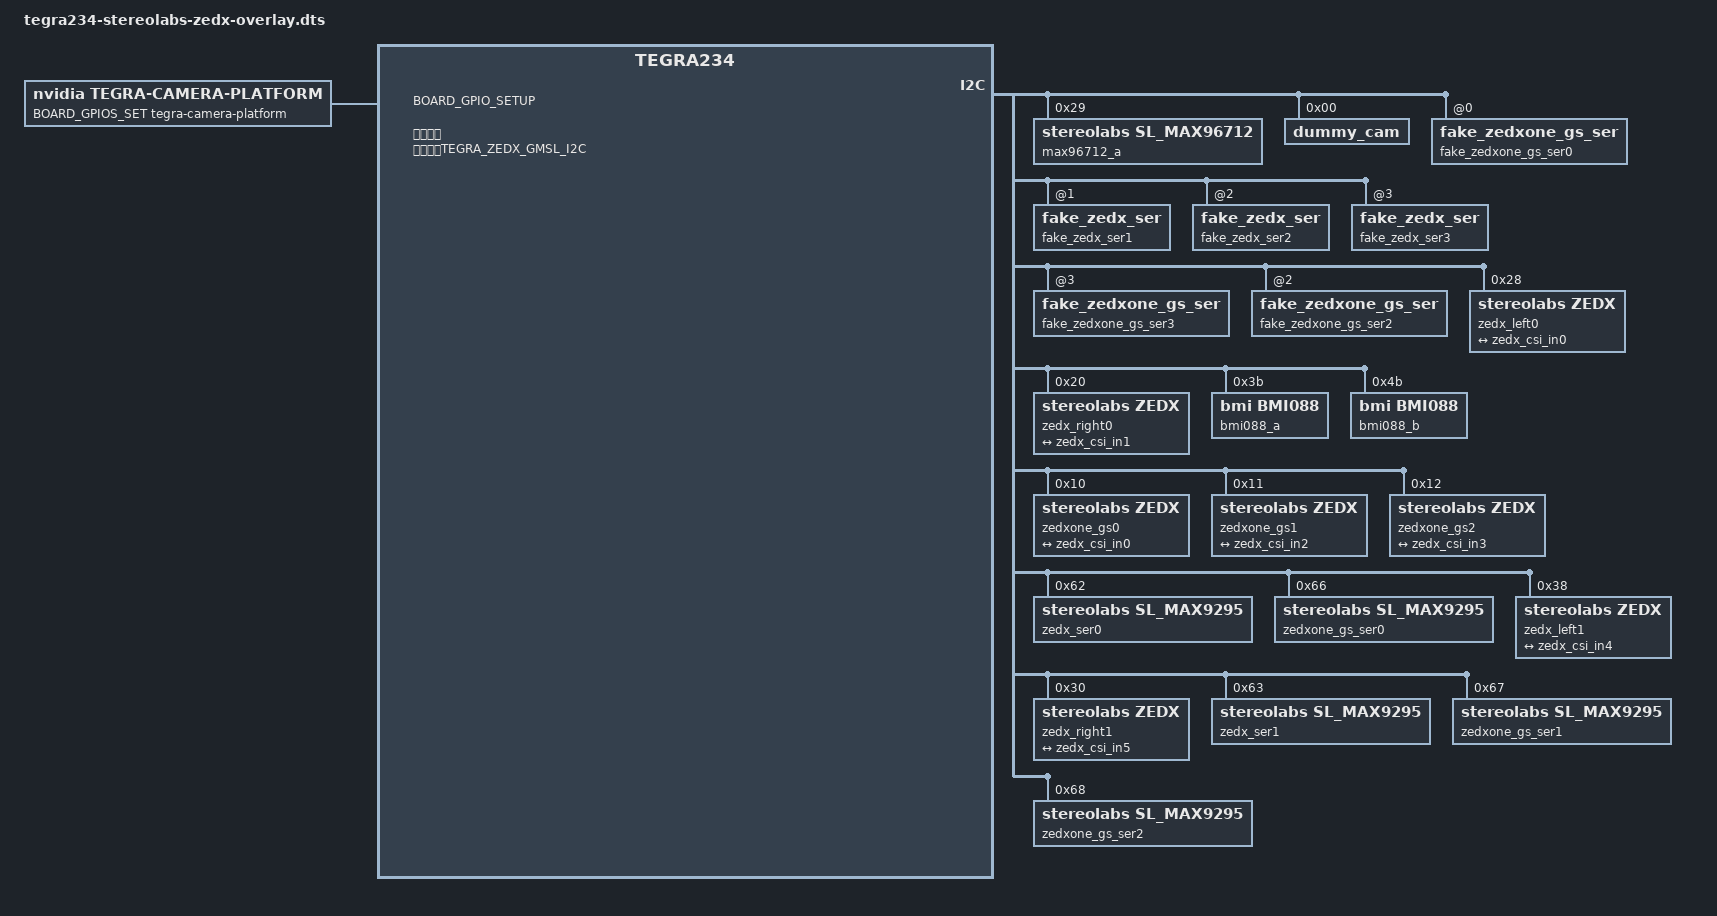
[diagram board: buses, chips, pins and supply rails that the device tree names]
// SPDX-License-Identifier: GPL-2.0-only
// Stereolabs ZED X / ZED X One GS GMSL overlay.

/dts-v1/;
/plugin/;

#include <dt-bindings/gpio/tegra234-gpio.h>
#include <dt-bindings/clock/tegra234-clock.h>
#include <dt-bindings/tegra234-p3737-0000+p3701-0000.h>
/* BOARD_CONFIG_MARKER - Do not modify, auto-generated by Makefile */
#include "tegra234-stereolabs-zedx-config.dtsi"

#define NUM_LANES	2

#define STR(x) #x
#define XSTR(x) STR(x)

#define ZED_ORIN_CLKS \
	clocks = <&bpmp TEGRA234_CLK_EXTPERIPH1>, \
		<&bpmp TEGRA234_CLK_EXTPERIPH1>; \
	clock-names = "extperiph1", "pllp_grtba"; \
	mclk = "extperiph1";

#define AR0234_MODES(VC_ID, OPT_CSI_SERIAL, LANE_POLARITY) \
	physical_w = "15.0"; \
	physical_h = "12.5"; \
	post_crop_frame_drop = "0"; \
	use_sensor_mode_id = "true"; \
	mode0 { \
		mclk_khz = "24000"; \
		num_lanes = XSTR(NUM_LANES); \
		tegra_sinterface = OPT_CSI_SERIAL; \
		lane_polarity = LANE_POLARITY; \
		vc_id = VC_ID; \
		discontinuous_clk = "no"; \
		dpcm_enable = "false"; \
		cil_settletime = "0"; \
		dynamic_pixel_bit_depth = "10"; \
		csi_pixel_bit_depth = "10"; \
		mode_type = "bayer"; \
		pixel_phase = "grbg"; \
		active_w = "1920"; \
		active_h = "1200"; \
		readout_orientation = "0"; \
		line_length = "12496"; \
		inherent_gain = "1"; \
		mclk_multiplier = "3.01"; \
		pix_clk_hz = "229500000"; \
		serdes_pix_clk_hz = "299000000"; \
		gain_factor = "100"; \
		min_gain_val = "100"; \
		max_gain_val = "1600"; \
		step_gain_val = "1"; \
		default_gain = "100"; \
		min_hdr_ratio = "1"; \
		max_hdr_ratio = "1"; \
		framerate_factor = "1000000"; \
		min_framerate = "15000000"; \
		max_framerate = "60000000"; \
		step_framerate = "15000000"; \
		default_framerate = "30000000"; \
		exposure_factor = "1000000"; \
		min_exp_time = "28"; \
		max_exp_time = "66000"; \
		step_exp_time = "1"; \
		default_exp_time = "13000"; \
		embedded_metadata_height = "0"; \
	}; \
	mode1 { \
		mclk_khz = "24000"; \
		num_lanes = XSTR(NUM_LANES); \
		tegra_sinterface = OPT_CSI_SERIAL; \
		lane_polarity = LANE_POLARITY; \
		vc_id = VC_ID; \
		discontinuous_clk = "no"; \
		dpcm_enable = "false"; \
		cil_settletime = "0"; \
		dynamic_pixel_bit_depth = "10"; \
		csi_pixel_bit_depth = "10"; \
		mode_type = "bayer"; \
		pixel_phase = "grbg"; \
		active_w = "960"; \
		active_h = "600"; \
		readout_orientation = "0"; \
		line_length = "6248"; \
		inherent_gain = "1"; \
		mclk_multiplier = "3.01"; \
		pix_clk_hz = "229500000"; \
		serdes_pix_clk_hz = "299000000"; \
		gain_factor = "100"; \
		min_gain_val = "100"; \
		max_gain_val = "1600"; \
		step_gain_val = "1"; \
		default_gain = "100"; \
		min_hdr_ratio = "1"; \
		max_hdr_ratio = "1"; \
		framerate_factor = "1000000"; \
		min_framerate = "15000000"; \
		max_framerate = "120000000"; \
		step_framerate = "15000000"; \
		default_framerate = "120000000"; \
		exposure_factor = "1000000"; \
		min_exp_time = "28"; \
		max_exp_time = "66000"; \
		step_exp_time = "1"; \
		default_exp_time = "8000"; \
		embedded_metadata_height = "0"; \
	}; \
	mode2 { \
		mclk_khz = "24000"; \
		num_lanes = XSTR(NUM_LANES); \
		tegra_sinterface = OPT_CSI_SERIAL; \
		lane_polarity = LANE_POLARITY; \
		vc_id = VC_ID; \
		discontinuous_clk = "no"; \
		dpcm_enable = "false"; \
		cil_settletime = "0"; \
		dynamic_pixel_bit_depth = "10"; \
		csi_pixel_bit_depth = "10"; \
		mode_type = "bayer"; \
		pixel_phase = "grbg"; \
		active_w = "1920"; \
		active_h = "1080"; \
		readout_orientation = "0"; \
		line_length = "12496"; \
		inherent_gain = "1"; \
		mclk_multiplier = "3.01"; \
		pix_clk_hz = "229500000"; \
		serdes_pix_clk_hz = "299000000"; \
		gain_factor = "100"; \
		min_gain_val = "100"; \
		max_gain_val = "1600"; \
		step_gain_val = "1"; \
		default_gain = "100"; \
		min_hdr_ratio = "1"; \
		max_hdr_ratio = "1"; \
		framerate_factor = "1000000"; \
		min_framerate = "15000000"; \
		max_framerate = "60000000"; \
		step_framerate = "15000000"; \
		default_framerate = "30000000"; \
		exposure_factor = "1000000"; \
		min_exp_time = "28"; \
		max_exp_time = "66000"; \
		step_exp_time = "1"; \
		default_exp_time = "13000"; \
		embedded_metadata_height = "0"; \
	};

/ {
	overlay-name = ZEDX_OVERLAY_NAME;
	jetson-header-name = "Jetson AGX CSI Connector";
	compatible = JETSON_COMPATIBLE;

	fragment@0 {
		target-path = "/";
		__overlay__ {
			tegra-capture-vi {
				num-channels = <6>;
				ports {
					#address-cells = <1>;
					#size-cells = <0>;

					port@0 {
						reg = <0>;
						zedx_vi_in0: endpoint {
							vc-id = <0>;
							port-index = <0>;
							bus-width = <NUM_LANES>;
							remote-endpoint = <&zedx_csi_out0>;
						};
					};

					port@1 {
						reg = <1>;
						zedx_vi_in1: endpoint {
							vc-id = <1>;
							port-index = <0>;
							bus-width = <NUM_LANES>;
							remote-endpoint = <&zedx_csi_out1>;
						};
					};

					port@2 {
						reg = <2>;
						zedx_vi_in2: endpoint {
							vc-id = <0>;
							port-index = <1>;
							bus-width = <NUM_LANES>;
							remote-endpoint = <&zedx_csi_out2>;
						};
					};

					port@3 {
						reg = <3>;
						zedx_vi_in3: endpoint {
							vc-id = <0>;
							port-index = <2>;
							bus-width = <NUM_LANES>;
							remote-endpoint = <&zedx_csi_out3>;
						};
					};

					port@4 {
						reg = <4>;
						zedx_vi_in4: endpoint {
							vc-id = <0>;
							port-index = <3>;
							bus-width = <NUM_LANES>;
							remote-endpoint = <&zedx_csi_out4>;
						};
					};

					port@5 {
						reg = <5>;
						zedx_vi_in5: endpoint {
							vc-id = <1>;
							port-index = <3>;
							bus-width = <NUM_LANES>;
							remote-endpoint = <&zedx_csi_out5>;
						};
					};
				};
			};

			BOARD_GPIOS_SET

			tegra-camera-platform {
				compatible = "nvidia, tegra-camera-platform";
				num_csi_lanes = <4>;
				max_lane_speed = <2000000>;
				min_bits_per_pixel = <10>;
				vi_peak_byte_per_pixel = <2>;
				vi_bw_margin_pct = <25>;
				isp_peak_byte_per_pixel = <5>;
				isp_bw_margin_pct = <25>;

				modules {
					module0 {
						badge = "zedx_left_ar0234";
						position = "frontleft";
						orientation = "1";
						drivernode0 {
							pcl_id = "v4l2_sensor";
							devname = ZEDX_DEVNAME_LEFT0;
							proc-device-tree = ZEDX_PROC_LEFT0;
						};
					};

					module1 {
						badge = "zedx_right_ar0234";
						position = "frontright";
						orientation = "1";
						drivernode0 {
							pcl_id = "v4l2_sensor";
							devname = ZEDX_DEVNAME_RIGHT0;
							proc-device-tree = ZEDX_PROC_RIGHT0;
						};
					};

					module2 {
						badge = "zedxone_gs1_ar0234";
						position = "front";
						orientation = "1";
						drivernode0 {
							pcl_id = "v4l2_sensor";
							devname = ZEDX_DEVNAME_ONE_GS1;
							proc-device-tree = ZEDX_PROC_ONE_GS1;
						};
					};

					module3 {
						badge = "zedxone_gs2_ar0234";
						position = "rear";
						orientation = "1";
						drivernode0 {
							pcl_id = "v4l2_sensor";
							devname = ZEDX_DEVNAME_ONE_GS2;
							proc-device-tree = ZEDX_PROC_ONE_GS2;
						};
					};

					module4 {
						badge = "zedx_left1_ar0234";
						position = "rearleft";
						orientation = "1";
						drivernode0 {
							pcl_id = "v4l2_sensor";
							devname = ZEDX_DEVNAME_LEFT1;
							proc-device-tree = ZEDX_PROC_LEFT1;
						};
					};

					module5 {
						badge = "zedx_right1_ar0234";
						position = "rearright";
						orientation = "1";
						drivernode0 {
							pcl_id = "v4l2_sensor";
							devname = ZEDX_DEVNAME_RIGHT1;
							proc-device-tree = ZEDX_PROC_RIGHT1;
						};
					};
				};
			};

			bus@0 {
				BOARD_GPIO_SETUP

				/* I2C bus 3 - MAX96712 DesA directly, no PCA9546 mux. */
				TEGRA_ZEDX_GMSL_I2C {
					#address-cells = <1>;
					#size-cells = <0>;

					max96712_a@29 {
						compatible = "stereolabs,sl_max96712";
						reg = <0x29>;
						channel = "a";
						pwr-gpio = ZEDX_DSER_PWR_GPIO;
						status = "okay";

						camera-serializers = <
							/* GMSL 0: ZED X */
							&zedx_ser0
							&fake_zedxone_gs_ser0
							/* GMSL 1: ZED X One GS */
							&fake_zedx_ser1
							&zedxone_gs_ser1
							/* GMSL 2: ZED X One GS */
							&fake_zedx_ser2
							&zedxone_gs_ser2
							/* GMSL 3: ZED X */
							&zedx_ser1
							&fake_zedxone_gs_ser3
						>;
					};

					dummy_cam: dummy_cam@0 {
						reg = <0>;
					};

					fake_zedxone_gs_ser0: fake_zedxone_gs_ser@0 {
						camera_model = "zedonegs";
						zedx-id = "-1";
						camera-sensors = <&dummy_cam>;
					};

					fake_zedx_ser1: fake_zedx_ser@1 {
						camera_model = "zedx";
						zedx-id = "-1";
						camera-sensors = <&dummy_cam &dummy_cam>;
					};

					fake_zedx_ser2: fake_zedx_ser@2 {
						camera_model = "zedx";
						zedx-id = "-1";
						camera-sensors = <&dummy_cam &dummy_cam>;
					};

					fake_zedx_ser3: fake_zedx_ser@3 {
						camera_model = "zedx";
						zedx-id = "-1";
						camera-sensors = <&dummy_cam &dummy_cam>;
					};

					fake_zedxone_gs_ser3: fake_zedxone_gs_ser@3 {
						camera_model = "zedonegs";
						zedx-id = "-1";
						camera-sensors = <&dummy_cam>;
					};

					/*
					 * Keep unused placeholders in the source so other physical
					 * plug orders can be tested by reordering camera-serializers.
					 */
					fake_zedxone_gs_ser2: fake_zedxone_gs_ser@2 {
						camera_model = "zedonegs";
						zedx-id = "-1";
						camera-sensors = <&dummy_cam>;
					};

					zedx_left0: zedx_left_0@28 {
						compatible = "stereolabs,zedx";
						reg = <0x28>;

						ZED_ORIN_CLKS

						devnode = "video0";
						sync_sensor = "ZED_CAM0";
						sync_sensor_index = <1>;

						zedx-id = "0";
						channel = "a";

						has-eeprom;
						eeprom-addr = <0x54>;

						AR0234_MODES("0", "serial_a", "0")

						ports {
							#address-cells = <1>;
							#size-cells = <0>;
							port@0 {
								reg = <0>;
								zedx_ar0234_out0: endpoint {
									vc-id = <0>;
									port-index = <0>;
									opt-csi-port = "e";
									bus-width = <NUM_LANES>;
									i2c-cc = <0>;
									remote-endpoint = <&zedx_csi_in0>;
								};
							};
						};
					};

					zedx_right0: zedx_right_0@20 {
						compatible = "stereolabs,zedx";
						reg = <0x20>;

						ZED_ORIN_CLKS

						devnode = "video1";
						sync_sensor = "ZED_CAM0";
						sync_sensor_index = <2>;

						zedx-id = "0";
						channel = "a";

						has-eeprom;
						eeprom-addr = <0x54>;

						AR0234_MODES("1", "serial_a", "0")

						ports {
							#address-cells = <1>;
							#size-cells = <0>;
							port@0 {
								reg = <0>;
								zedx_ar0234_out1: endpoint {
									vc-id = <1>;
									port-index = <0>;
									opt-csi-port = "e";
									bus-width = <NUM_LANES>;
									i2c-cc = <0>;
									remote-endpoint = <&zedx_csi_in1>;
								};
							};
						};
					};

					bmi088_a: bmi088_a@3b {
						compatible = "bmi,bmi088";
						reg = <0x3b>;
						accel_i2c_addr = <0x3c>;
						accel_matrix = [01 00 00 00 01 00 00 00 01];
						gyro_matrix = [01 00 00 00 01 00 00 00 01];
					};

					bmi088_b: bmi088_b@4b {
						compatible = "bmi,bmi088";
						reg = <0x4b>;
						accel_i2c_addr = <0x4c>;
						accel_matrix = [01 00 00 00 01 00 00 00 01];
						gyro_matrix = [01 00 00 00 01 00 00 00 01];
					};

					zedxone_gs0: zedxone_gs_0@10 {
						compatible = "stereolabs,zedx";
						reg = <0x10>;

						ZED_ORIN_CLKS

						devnode = "video0";
						sync_sensor = "ZEDXONE_CAM0";
						sync_sensor_index = <1>;

						zedx-id = "4";
						channel = "a";

						has-eeprom;
						eeprom-addr = <0x56>;

						AR0234_MODES("0", "serial_a", "0")

						ports {
							#address-cells = <1>;
							#size-cells = <0>;
							port@0 {
								reg = <0>;
								zedxone_gs_out0: endpoint {
									vc-id = <0>;
									port-index = <0>;
									opt-csi-port = "e";
									bus-width = <NUM_LANES>;
									i2c-cc = <0>;
									remote-endpoint = <&zedx_csi_in0>;
								};
							};
						};
					};

					zedxone_gs1: zedxone_gs_1@11 {
						compatible = "stereolabs,zedx";
						reg = <0x11>;

						ZED_ORIN_CLKS

						devnode = "video2";
						sync_sensor = "ZEDXONE_CAM1";
						sync_sensor_index = <1>;

						zedx-id = "5";
						channel = "a";

						has-eeprom;
						eeprom-addr = <0x56>;

						AR0234_MODES("0", "serial_b", "0")

						ports {
							#address-cells = <1>;
							#size-cells = <0>;
							port@0 {
								reg = <0>;
								zedxone_gs_out1: endpoint {
									vc-id = <0>;
									port-index = <1>;
									opt-csi-port = "f";
									bus-width = <NUM_LANES>;
									i2c-cc = <0>;
									remote-endpoint = <&zedx_csi_in2>;
								};
							};
						};
					};

					zedxone_gs2: zedxone_gs_2@12 {
						compatible = "stereolabs,zedx";
						reg = <0x12>;

						ZED_ORIN_CLKS

						devnode = "video3";
						sync_sensor = "ZEDXONE_CAM2";
						sync_sensor_index = <1>;

						zedx-id = "6";
						channel = "a";

						has-eeprom;
						eeprom-addr = <0x56>;

						AR0234_MODES("0", "serial_c", "0")

						ports {
							#address-cells = <1>;
							#size-cells = <0>;
							port@0 {
								reg = <0>;
								zedxone_gs_out2: endpoint {
									vc-id = <0>;
									port-index = <2>;
									opt-csi-port = "c";
									bus-width = <NUM_LANES>;
									i2c-cc = <0>;
									remote-endpoint = <&zedx_csi_in3>;
								};
							};
						};
					};

					zedx_ser0: zedx_ser_0@62 {
						compatible = "stereolabs,sl_max9295";
						reg = <0x62>;
						zedx-id = "0";
						channel = "a";
						mode = "master";
						camera_model = "zedx";
						camera-sensors = <&zedx_left0 &zedx_right0>;
						imu = <&bmi088_a &bmi088_b>;
					};

					zedxone_gs_ser0: zedxone_gs_ser_0@66 {
						compatible = "stereolabs,sl_max9295";
						reg = <0x66>;
						zedx-id = "4";
						channel = "a";
						mode = "master";
						camera_model = "zedonegs";
						camera-sensors = <&zedxone_gs0>;
						imu = <&bmi088_a &bmi088_b>;
					};

					zedx_left1: zedx_left_1@38 {
						compatible = "stereolabs,zedx";
						reg = <0x38>;

						ZED_ORIN_CLKS

						devnode = "video4";
						sync_sensor = "ZED_CAM1";
						sync_sensor_index = <1>;

						zedx-id = "1";
						channel = "a";

						has-eeprom;
						eeprom-addr = <0x54>;

						AR0234_MODES("0", "serial_d", "0")

						ports {
							#address-cells = <1>;
							#size-cells = <0>;
							port@0 {
								reg = <0>;
								zedx_ar0234_out2: endpoint {
									vc-id = <0>;
									port-index = <3>;
									opt-csi-port = "d";
									bus-width = <NUM_LANES>;
									i2c-cc = <0>;
									remote-endpoint = <&zedx_csi_in4>;
								};
							};
						};
					};

					zedx_right1: zedx_right_1@30 {
						compatible = "stereolabs,zedx";
						reg = <0x30>;

						ZED_ORIN_CLKS

						devnode = "video5";
						sync_sensor = "ZED_CAM1";
						sync_sensor_index = <2>;

						zedx-id = "1";
						channel = "a";

						has-eeprom;
						eeprom-addr = <0x54>;

						AR0234_MODES("1", "serial_d", "0")

						ports {
							#address-cells = <1>;
							#size-cells = <0>;
							port@0 {
								reg = <0>;
								zedx_ar0234_out3: endpoint {
									vc-id = <1>;
									port-index = <3>;
									opt-csi-port = "d";
									bus-width = <NUM_LANES>;
									i2c-cc = <0>;
									remote-endpoint = <&zedx_csi_in5>;
								};
							};
						};
					};

					zedx_ser1: zedx_ser_1@63 {
						compatible = "stereolabs,sl_max9295";
						reg = <0x63>;
						zedx-id = "1";
						channel = "a";
						mode = "master";
						camera_model = "zedx";
						camera-sensors = <&zedx_left1 &zedx_right1>;
						imu = <&bmi088_a &bmi088_b>;
					};

					zedxone_gs_ser1: zedxone_gs_ser_1@67 {
						compatible = "stereolabs,sl_max9295";
						reg = <0x67>;
						zedx-id = "5";
						channel = "a";
						mode = "master";
						camera_model = "zedonegs";
						camera-sensors = <&zedxone_gs1>;
						imu = <&bmi088_a &bmi088_b>;
					};

					zedxone_gs_ser2: zedxone_gs_ser_2@68 {
						compatible = "stereolabs,sl_max9295";
						reg = <0x68>;
						zedx-id = "6";
						channel = "a";
						mode = "master";
						camera_model = "zedonegs";
						camera-sensors = <&zedxone_gs2>;
						imu = <&bmi088_a &bmi088_b>;
					};
				};

				host1x@13e00000 {
					nvcsi@15a00000 {
						num-channels = <6>;
						#address-cells = <1>;
						#size-cells = <0>;

						channel@0 {
							reg = <0>;
							ports {
								#address-cells = <1>;
								#size-cells = <0>;
								port@0 {
									reg = <0>;
									zedx_csi_in0: endpoint@0 {
										port-index = <0>;
										bus-width = <NUM_LANES>;
										remote-endpoint = <&zedx_ar0234_out0>;
									};
								};
								port@1 {
									reg = <1>;
									zedx_csi_out0: endpoint@1 {
										remote-endpoint = <&zedx_vi_in0>;
									};
								};
							};
						};

						channel@1 {
							reg = <1>;
							ports {
								#address-cells = <1>;
								#size-cells = <0>;
								port@0 {
									reg = <0>;
									zedx_csi_in1: endpoint@2 {
										port-index = <0>;
										bus-width = <NUM_LANES>;
										remote-endpoint = <&zedx_ar0234_out1>;
									};
								};
								port@1 {
									reg = <1>;
									zedx_csi_out1: endpoint@3 {
										remote-endpoint = <&zedx_vi_in1>;
									};
								};
							};
						};

						channel@2 {
							reg = <2>;
							ports {
								#address-cells = <1>;
								#size-cells = <0>;
								port@0 {
									reg = <0>;
									zedx_csi_in2: endpoint@4 {
										port-index = <1>;
										bus-width = <NUM_LANES>;
										remote-endpoint = <&zedxone_gs_out1>;
									};
								};
								port@1 {
									reg = <1>;
									zedx_csi_out2: endpoint@5 {
										remote-endpoint = <&zedx_vi_in2>;
									};
								};
							};
						};

						channel@3 {
							reg = <3>;
							ports {
								#address-cells = <1>;
								#size-cells = <0>;
								port@0 {
									reg = <0>;
									zedx_csi_in3: endpoint@6 {
										port-index = <2>;
										bus-width = <NUM_LANES>;
										remote-endpoint = <&zedxone_gs_out2>;
									};
								};
								port@1 {
									reg = <1>;
									zedx_csi_out3: endpoint@7 {
										remote-endpoint = <&zedx_vi_in3>;
									};
								};
							};
						};

						channel@4 {
							reg = <4>;
							ports {
								#address-cells = <1>;
								#size-cells = <0>;
								port@0 {
									reg = <0>;
									zedx_csi_in4: endpoint@8 {
										port-index = <3>;
										bus-width = <NUM_LANES>;
										remote-endpoint = <&zedx_ar0234_out2>;
									};
								};
								port@1 {
									reg = <1>;
									zedx_csi_out4: endpoint@9 {
										remote-endpoint = <&zedx_vi_in4>;
									};
								};
							};
						};

						channel@5 {
							reg = <5>;
							ports {
								#address-cells = <1>;
								#size-cells = <0>;
								port@0 {
									reg = <0>;
									zedx_csi_in5: endpoint@10 {
										port-index = <3>;
										bus-width = <NUM_LANES>;
										remote-endpoint = <&zedx_ar0234_out3>;
									};
								};
								port@1 {
									reg = <1>;
									zedx_csi_out5: endpoint@11 {
										remote-endpoint = <&zedx_vi_in5>;
									};
								};
							};
						};
					};
				};
			};
		};
	};
};
